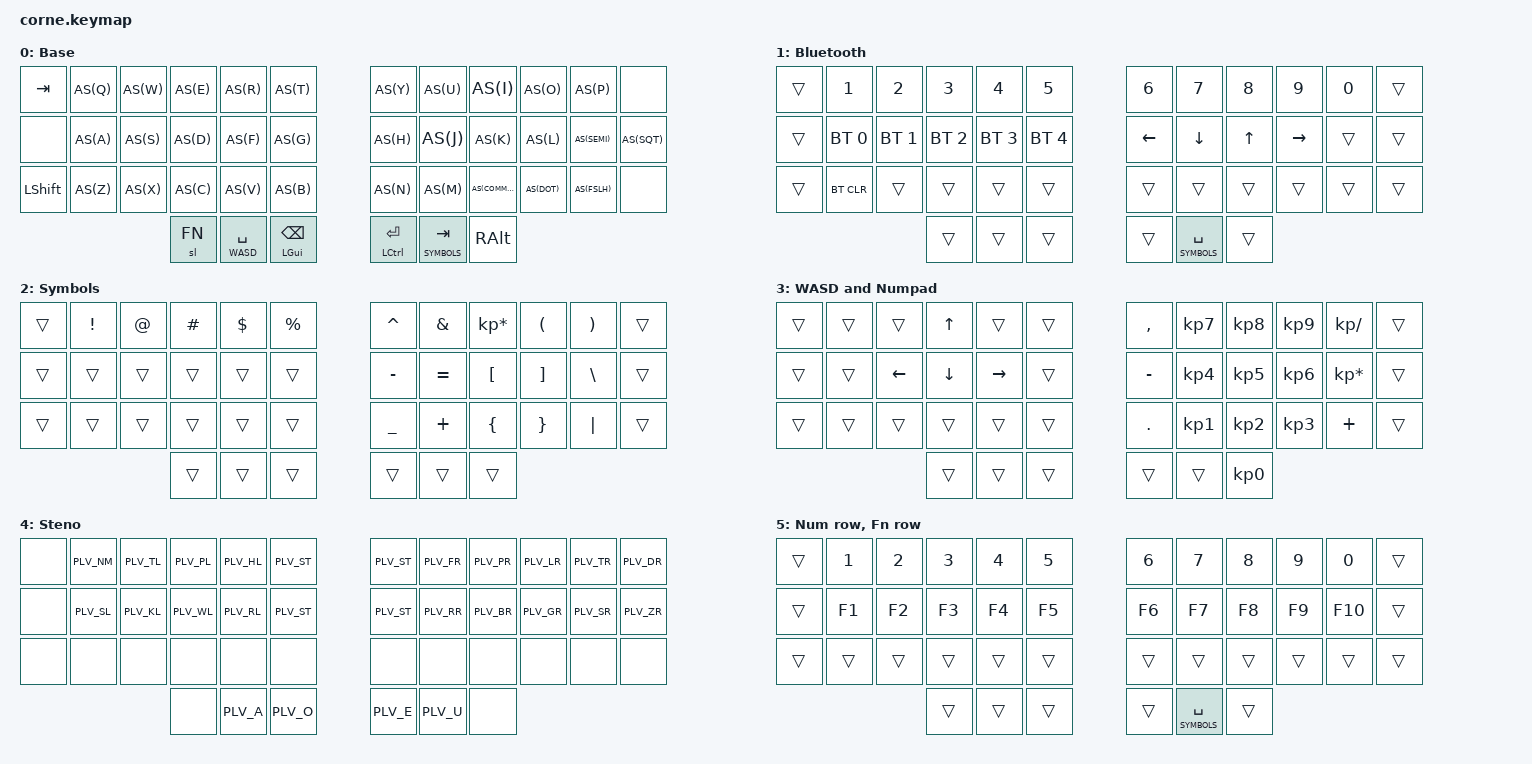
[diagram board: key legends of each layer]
/*
 * Copyright (c) 2020 The ZMK Contributors
 *
 * SPDX-License-Identifier: MIT
 */

#include <behaviors.dtsi>
#include <dt-bindings/zmk/keys.h>
#include <dt-bindings/zmk/bt.h>

#define DEFAULT 0
#define BT 1
#define SYMBOLS 2
#define WASD 3
#define STENO 4
#define FN 5
#define ARDUX_LAYER 6

#define ALL_LAYERS_NO_ARDUX <0 1 2 3 4 5>
#define ARDUX_LAYERS <6 7 8 9 10 11 12 13 14 15>
#define QWERTY_CHAR_LAYERS <DEFAULT SYMBOLS FN>

#define AS(keycode) &as LS(keycode) keycode     // Autoshift Macro

#define combo_length 30

&lt { quick_tap_ms = <200>; };
&mt { quick_tap_ms = <200>; };

/ {
  macros {
    ZMK_MACRO(spotlight_macro,
      wait-ms = <30>;
      tap-ms = <40>;
      bindings = <&macro_press &kp LGUI>
              , <&macro_tap &kp SPACE>
              , <&macro_release &kp LGUI>;
    )

    ZMK_MACRO(emdash_macro,
      wait-ms = <30>;
      tap-ms = <40>;
      bindings = <&macro_press &kp LSHIFT>
              , <&macro_press &kp LALT>
              , <&macro_tap &kp MINUS>
              , <&macro_release &kp LALT>
              , <&macro_release &kp LSHIFT>;
    )
  };

  combos {
    compatible = "zmk,combos";
    combo_tilde {
      timeout-ms = <combo_length>;
      key-positions = <13 14>;
      bindings = <&kp TILDE>;
      layers = QWERTY_CHAR_LAYERS;
    };
    combo_backtick {
      timeout-ms = <combo_length>;
      key-positions = <25 26>;
      bindings = <&kp GRAVE>;
      layers = QWERTY_CHAR_LAYERS;
    };
    combo_emdash {
      timeout-ms = <combo_length>;
      key-positions = <18 19 20>;
      bindings = <&emdash_macro>;
      layers = QWERTY_CHAR_LAYERS;
    };         
    combo_hyphen {
      timeout-ms = <combo_length>;
      key-positions = <18 19>;
      bindings = <&kp MINUS>;
      layers = QWERTY_CHAR_LAYERS;
    };
    combo_underscore {
      timeout-ms = <combo_length>;
      key-positions = <30 31>;
      bindings = <&kp UNDER>;
      layers = QWERTY_CHAR_LAYERS;
    };
    combo_paren_open {
      timeout-ms = <combo_length>;
      key-positions = <8 9>;
      bindings = <&kp LPAR>;
      layers = QWERTY_CHAR_LAYERS;
    };
    combo_paren_close {
      timeout-ms = <combo_length>;
      key-positions = <9 10>;
      bindings = <&kp RPAR>;
      layers = QWERTY_CHAR_LAYERS;
    };
    combo_squarebracket_open {
      timeout-ms = <combo_length>;
      key-positions = <20 21>;
      bindings = <&kp LBKT>;
      layers = QWERTY_CHAR_LAYERS;
    };
    combo_squarebracket_close {
      timeout-ms = <combo_length>;
      key-positions = <21 22>;
      bindings = <&kp RBKT>;
      layers = QWERTY_CHAR_LAYERS;
    };
    combo_curlybracket_open {
      timeout-ms = <combo_length>;
      key-positions = <32 33>;
      bindings = <&kp LBRC>;
      layers = QWERTY_CHAR_LAYERS;
    };
    combo_curlybracket_close {
      timeout-ms = <combo_length>;
      key-positions = <33 34>;
      bindings = <&kp RBRC>;
      layers = QWERTY_CHAR_LAYERS;
    };
    combo_spotlight {
      timeout-ms = <50>;
      key-positions = <38 39>;
      bindings = <&spotlight_macro>;
      layers = QWERTY_CHAR_LAYERS;
    };
    combo_bt {
      timeout-ms = <50>;
      key-positions = <1 2 3 4>;
      bindings = <&sl BT>;
      layers = QWERTY_CHAR_LAYERS;
    };  
 
    combo_esc {
      timeout-ms = <combo_length>;
      key-positions = <0 1>;
      bindings = <&kp ESC>;
      layers = QWERTY_CHAR_LAYERS;
    };
    combo_ardux {
      timeout-ms = <50>;
      key-positions = <25 26 27 28>;
      bindings = <&tog ARDUX_LAYER>;
    };
    combo_steno {
      timeout-ms = <50>;
      key-positions = <36 41>;
      bindings = <&tog STENO>;
    };
    // combo_nextwindow {
    //   timeout-ms = <combo_length>;
    //   key-positions = <4 17>;
    //   bindings = <&nextwindow_macro>;
    // };
    // combo_previouswindow {
    //   timeout-ms = <combo_length>;
    //   key-positions = <3 16>;
    //   bindings = <&kp LGUI &kp LSHIFT &kp TAB>;
    // };   
    // combo_previoustab {
    //   timeout-ms = <combo_length>;
    //   key-positions = <7 18>;
    //   bindings = <&kp LGUI &kp LSHIFT &kp LBKT>;
    // };
    // combo_nexttab {
    //   timeout-ms = <combo_length>;
    //   key-positions = <8 19>;
    //   bindings = <&kp LGUI &kp LSHIFT &kp RBKT>;
    // };     
  };

  behaviors {
    ctrl_caps: ctrl_caps {
      compatible = "zmk,behavior-tap-dance";
      #binding-cells = <0>;
      tapping-term-ms = <200>;
      bindings = <&kp LCTRL>, <&kp CAPS>;
    };

     as: auto_shift {
            compatible = "zmk,behavior-hold-tap";
            #binding-cells = <2>;
            tapping_term_ms = <170>;
            quick_tap_ms = <0>;
            flavor = "tap-preferred";
            bindings = <&kp>, <&kp>;
        };
  };

  keymap {
    compatible = "zmk,keymap";

    default_layer {
// -----------------------------------------------------------------------------------------
// |  TAB |  Q  |  W  |  E  |  R  |  T  |   |  Y  |  U   |  I  |  O  |  P  | BKSP |
// | CTRL |  A  |  S  |  D  |  F  |  G  |   |  H  |  J   |  K  |  L  |  ;  |  '   |
// | SHFT |  Z  |  X  |  C  |  V  |  B  |   |  N  |  M   |  ,  |  .  |  /  | ESC  |
//                    | GUI | LWR | SPC |   | ENT | RSE  | ALT |
      display-name = "Base";
      bindings = <
   &kp TAB   AS(Q) AS(W) AS(E) AS(R) AS(T)   AS(Y) AS(U)  AS(I)     AS(O)   AS(P)    /*&kp BSPC*/ &none 
   /*&ctrl_caps*/ &none AS(A) AS(S) AS(D) AS(F) AS(G)   AS(H) AS(J)  AS(K)     AS(L)   AS(SEMI) AS(SQT) 
   &kp LSHFT AS(Z) AS(X) AS(C) AS(V) AS(B)   AS(N) AS(M)  AS(COMMA) AS(DOT) AS(FSLH) /*&kp ESC*/ &none 
      &sl FN &lt WASD SPACE &mt LGUI BSPC   &mt LCTRL RET &lt SYMBOLS TAB &kp RALT
      >;
    };
    bt_layer {
// -----------------------------------------------------------------------------------------
// |  TAB |  1  |  2  |  3  |  4  |  5  |   |  6  |  7  |  8  |  9  |  0  | BKSP |
// | BTCLR| BT1 | BT2 | BT3 | BT4 | BT5 |   | LFT | DWN |  UP | RGT |     |      |
// | SHFT |     |     |     |     |     |   |     |     |     |     |     |      |
//                    | GUI |     | SPC |   | ENT |     | ALT |
      display-name = "Bluetooth";
      bindings = <
   &trans    &kp N1       &kp N2       &kp N3       &kp N4       &kp N5         &kp N6   &kp N7   &kp N8 &kp N9    &kp N0 &trans
   &trans &bt BT_SEL 0 &bt BT_SEL 1 &bt BT_SEL 2 &bt BT_SEL 3 &bt BT_SEL 4   &kp LEFT &kp DOWN &kp UP &kp RIGHT &trans &trans
   &trans &bt BT_CLR         &trans       &trans       &trans       &trans         &trans   &trans   &trans &trans    &trans &trans
            &trans     &trans       &trans      &trans  &lt SYMBOLS SPACE   &trans
      >;
    };

    sym_layer {
// -----------------------------------------------------------------------------------------
// |  TAB |  !  |  @  |  #  |  $  |  %  |   |  ^  |  &  |  *  |  (  |  )  | BKSP |
// | CTRL |     |     |     |     |     |   |  -  |  =  |  [  |  ]  |  \  |  `   |
// | SHFT |     |     |     |     |     |   |  _  |  +  |  {  |  }  | "|" |  ~   |
      display-name = "Symbols";
      bindings = <
   &trans  &kp EXCL &kp AT &kp HASH &kp DLLR &kp PRCNT   &kp CARET &kp AMPS  &kp KP_MULTIPLY &kp LPAR &kp RPAR &trans
   &trans &trans   &trans &trans   &trans   &trans      &kp MINUS &kp EQUAL &kp LBKT        &kp RBKT &kp BSLH /*&kp GRAVE*/ &trans
   &trans &trans   &trans &trans   &trans   &trans      &kp UNDER &kp PLUS  &kp LBRC        &kp RBRC &kp PIPE /*&kp TILDE*/ &trans
               &trans &trans   &trans   &trans   &trans    &trans
      >;
    };
  wasd_layer {
// -----------------------------------------------------------------------------------------
// |  TAB |     |  W  |     |     |     |   |  ,  |  7  |  8  |  9  |  /  |     |
// | CTRL |  A  |  S  |  D  |     |     |   |  -  |  4  |  5  |  6  |  *  |      |
// | SHFT |     |     |     |     |     |   |  .  |  1 |  2  |  3  |  +  |      |
//                    |     |     |     |   |     |     |    |
      display-name = "WASD and Numpad";
      bindings = <
   &trans &trans &trans &kp UP &trans &trans   &kp COMMA &kp KP_N7  &kp KP_N8 &kp KP_N9 &kp KP_DIVIDE &trans
&trans &trans &kp LEFT  &kp DOWN &kp RIGHT   &trans     &kp MINUS &kp KP_N4 &kp KP_N5  &kp KP_N6 &kp KP_MULTIPLY &trans
   &trans &trans   &trans &trans   &trans   &trans      &kp DOT &kp KP_N1  &kp KP_N2  &kp KP_N3 &kp PLUS &trans
               &trans &trans   &trans   &trans   &trans    &kp KP_N0
      >;
    };

//    -----------------------------------------------------------------------------------------
// |     |  #  |  T  |  P  |  H  |  *  |   |  *  |  F  |  P  |  L  |  T  |  D  |
// |     |  S  |  K  |  W  |  R  |  *  |   |  *  |  R  |  B  |  G  |  S  |  Z  |
// |     |     |     |     |  A  |  O  |   |  E  |  U  |     |     |     |    |
//   

    steno_layer {
      display-name = "Steno";
      bindings = <
&none &kp PLV_NM &kp PLV_TL &kp PLV_PL &kp PLV_HL &kp PLV_ST   &kp PLV_ST &kp PLV_FR &kp PLV_PR &kp PLV_LR &kp PLV_TR &kp PLV_DR
&none &kp PLV_SL &kp PLV_KL &kp PLV_WL &kp PLV_RL &kp PLV_ST   &kp PLV_ST &kp PLV_RR &kp PLV_BR &kp PLV_GR &kp PLV_SR &kp PLV_ZR
&none &none &none &none &none &none   &none &none &none &none &none &none
               &none &kp PLV_A   &kp PLV_O   &kp PLV_E   &kp PLV_U    &none
      >;
    };

    function_layer {
      display-name = "Num row, Fn row";
      bindings = <
         &trans    &kp N1       &kp N2       &kp N3       &kp N4       &kp N5         &kp N6   &kp N7   &kp N8 &kp N9    &kp N0 &trans
  /*&kp F12*/ &trans &kp F1 &kp F2 &kp F3 &kp F4 &kp F5			&kp F6 &kp F7 &kp F8 &kp F9 &kp F10 &trans
   &trans  &trans       &trans       &trans       &trans       &trans         &trans   &trans   &trans &trans    &trans &trans
            &trans     &trans       &trans      &trans  &lt SYMBOLS SPACE   &trans
      >;
    };
  };
};

// Setup left ardux
// Taken from github:arduxio/zmk-ardux/config/boards/shields/corne_left/corne_ardux_left.keymap

// Enable ARDUX Left
#define ARDUX_LEFT 1

#define ARDUX_BIG 1

// ARTS Row
#define KEY_A 4
#define KEY_R 3
#define KEY_T 2
#define KEY_S 1

// EYIO Row
// Original repo numbers didn't assume a right half
#define KEY_E 16
#define KEY_Y 15
#define KEY_I 14
#define KEY_O 13

// Big ardux F1-12 layer keys for combo
// If using these, update offsets
#define KEY_F_TOP 5
#define KEY_F_BOTTOM 17

// I had defined the whitespace constants here,
// but they have to be after NONE is defined,
// so they've been moved into the DTSI

// I deleted some definitions like THUMB_1, 
// need to figure out how to handle thumbs and exiting

// Finally include Ardux itself
#include "ardux.dtsi"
